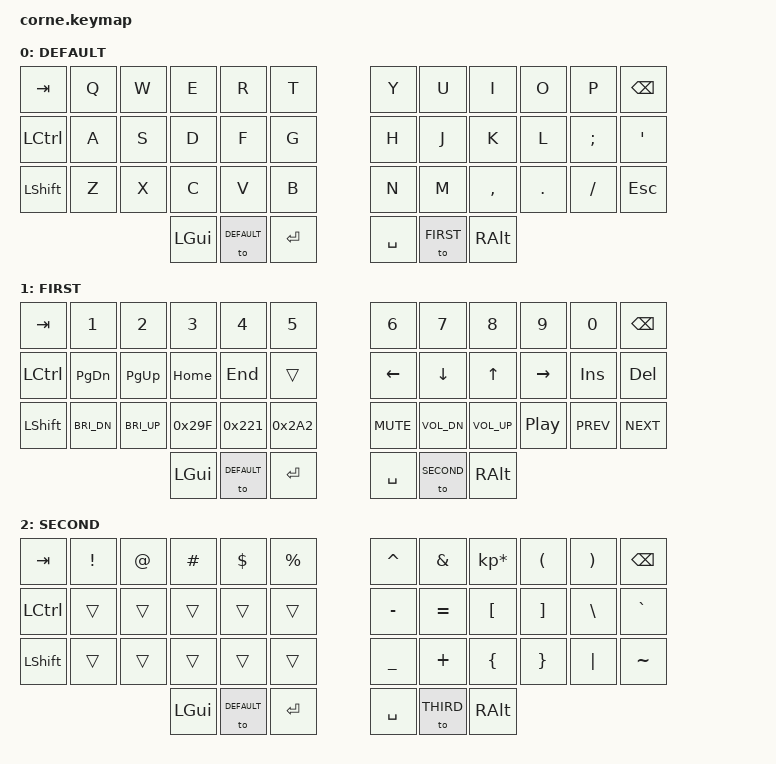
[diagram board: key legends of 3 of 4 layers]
/*
 * Copyright (c) 2020 The ZMK Contributors
 *
 * SPDX-License-Identifier: MIT
 */

#include <behaviors.dtsi>
#include <dt-bindings/zmk/keys.h>
#include <dt-bindings/zmk/bt.h>

#define DEFAULT 0
#define FIRST   1
#define SECOND   2
#define THIRD   3

/ {
        combos {
        compatible = "zmk,combos";
        
        combo_rshft {
            timeout-ms = <50>;
            key-positions = <34 35>;
            bindings = <&kp RSHFT>;
        };

        combo_del {
            timeout-ms = <50>;
            key-positions = <10 11>;
            bindings = <&kp DEL>;
        };

        combo_caps {
            timeout-ms = <50>;
            key-positions = <24 25>;
            bindings = <&kp CAPS>;
        };
        
     };

        keymap {
                compatible = "zmk,keymap";

                DEFAULT {
// -----------------------------------------------------------------------------------------
// |  TAB |  Q  |  W  |  E  |  R  |  T  |   |  Y  |  U   |  I  |  O  |  P  | BKSP |
// | CTRL |  A  |  S  |  D  |  F  |  G  |   |  H  |  J   |  K  |  L  |  ;  |  '   |
// | SHFT |  Z  |  X  |  C  |  V  |  B  |   |  N  |  M   |  ,  |  .  |  /  | ESC  |
//                    | GUI | LWR | SPC |   | ENT | RSE  | ALT |
                        bindings = <
   &kp TAB   &kp Q &kp W &kp E &kp R &kp T   &kp Y &kp U  &kp I     &kp O   &kp P    &kp BSPC
   &kp LCTRL &kp A &kp S &kp D &kp F &kp G   &kp H &kp J  &kp K     &kp L   &kp SEMI &kp SQT
   &kp LSHFT &kp Z &kp X &kp C &kp V &kp B   &kp N &kp M  &kp COMMA &kp DOT &kp FSLH &kp ESC
              &kp LGUI &to DEFAULT &kp RET   &kp SPACE &to FIRST &kp RALT
                        >;
                };

                FIRST {
// -----------------------------------------------------------------------------------------
// |  TAB  |  1     |  2     |  3   |  4   |  5  |   |  6  |  7  |  8  |  9  |  0  | BKSP |
// | LCTRL | PG_DN  | PG_UP  | HOME | END  |     |   | LFT | DWN |  UP | RGT |     |      |
// | SHFT  | BRI_DN | BRI_UP | MCTR | SRCH | LPD |   | MUT | VDN | VUP |     |     |      |
//                           | GUI  |      | ENT |   | SPC |     | ALT |
                       bindings = <
   &kp TAB    &kp N1       &kp N2       &kp N3          &kp N4          &kp N5             &kp N6      &kp N7         &kp N8        &kp N9    &kp N0      &kp BSPC
   &kp LCTRL  &kp PG_DN    &kp PG_UP    &kp HOME        &kp END         &trans             &kp LEFT    &kp DOWN       &kp UP        &kp RIGHT &kp INS     &kp DEL
   &kp LSHFT  &kp C_BRI_DN &kp C_BRI_UP &kp 0x29F       &kp 0x221       &kp 0x2A2          &kp C_MUTE  &kp C_VOL_DN   &kp C_VOL_UP  &kp C_PP  &kp C_PREV  &kp C_NEXT
                          	        &kp LGUI        &to DEFAULT     &kp RET            &kp SPACE   &to SECOND   &kp RALT
                        >;
                };

                SECOND {

// -----------------------------------------------------------------------------------------
// |  TAB  |  !    |  @   |  #  |  $  |  %  |   |  ^  |  &  |  *  |  (  |  )  | BKSP |
// | LCTRL |  BT1  |  BT2 | BT3 | BT4 | BT5 |   |  -  |  =  |  [  |  ]  |  \  |  `   |
// | SHFT  |       |      |     |     |     |   |  _  |  +  |  {  |  }  | "|" |  ~   |
//                        | GUI |     | SPC |   | ENT |     | ALT |
                        bindings = <
   &kp  TAB     &kp EXCL  &kp AT       &kp HASH     &kp DLLR     &kp PRCNT      &kp CARET &kp AMPS  &kp KP_MULTIPLY &kp LPAR &kp RPAR &kp BSPC
   &kp LCTRL    &trans    &trans       &trans       &trans       &trans         &kp MINUS &kp EQUAL &kp LBKT        &kp RBKT &kp BSLH &kp GRAVE
   &kp LSHFT    &trans    &trans       &trans       &trans       &trans         &kp UNDER &kp PLUS  &kp LBRC        &kp RBRC &kp PIPE &kp TILDE
                    	             &kp LGUI       &to DEFAULT  &kp RET        &kp SPACE &to THIRD &kp RALT
                        >;
                };

                THIRD {
// -----------------------------------------------------------------------------------------
// |  F1   |  F2   |  F3  |  F4 |  F5 |  F6 |   |  F7 |  F8 |  F9 | F10 | F11 | F12  |
// | BTCLR |  BT1  |  BT2 | BT3 | BT4 | BT5 |   |     |     |     |     |     |      |
// |       |       |      |     |     |     |   |     |     |     |     |     |      |
//                    | GUI |     | SPC |   | ENT |     | ALT |
                        bindings = <
   &kp  F1   &kp F2   &kp F3 &kp F4   &kp F5   &kp F6              &kp F7    &kp F8    &kp F9     &kp F10  &kp F11  &kp F12
   &bt BT_CLR &bt BT_SEL 0 &bt BT_SEL 1 &bt BT_SEL 2 &bt BT_SEL 3  &trans    &trans    &trans     &trans   &trans   &trans 
   &trans    &trans   &trans &trans   &trans   &trans              &trans    &trans    &trans     &trans   &trans   &trans 
                    	     &kp LGUI &to DEFAULT    &kp RET       &kp SPACE   &to DEFAULT    &kp RALT
                        >;
                };
        };
};
